# RX64M_IWDT_Pilot register map
File version: 1.0
RX64M_IWDT_Pilot peripheral registers generated from iodefine.h (pilot).
Registers are 8-bit, read-write, reset 0x80 unless marked. A register's access mark holds for its fields unless they carry their own. Offsets are from the block's base; lines under a group give offsets from that group; [hi:lo] are bit positions; {n}, {i} and the like mark numbered series; 'fields as' and 'values as' point back to an identical list; <NAME> marks a mode.

## Memory map
0x00088030 IWDT size 0x9

## IWDT
Base 0x00088030
0x00 IWDTRR reset 0xFF
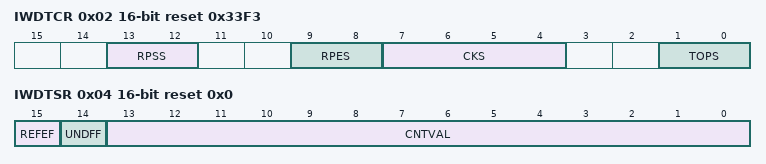
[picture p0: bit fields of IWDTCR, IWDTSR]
0x02 IWDTCR 16-bit reset 0x33F3
  [13:12] RPSS, [9:8] RPES, [7:4] CKS, [1:0] TOPS
0x04 IWDTSR 16-bit reset 0x0
  [15] REFEF, [14] UNDFF, [13:0] CNTVAL
0x06 IWDTRCR
  [7] RSTIRQS
0x08 IWDTCSTPR
  [7] SLCSTP
